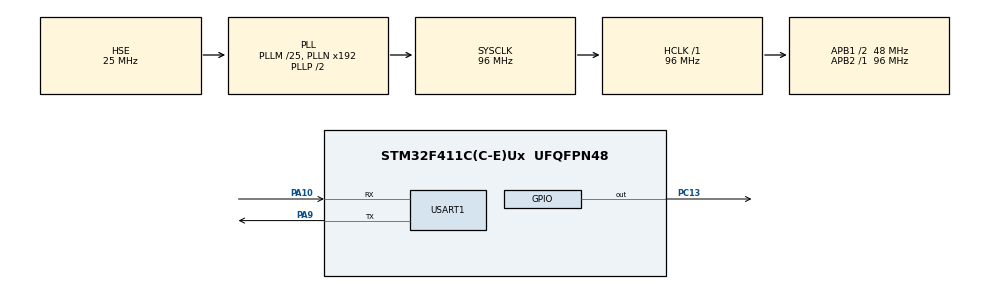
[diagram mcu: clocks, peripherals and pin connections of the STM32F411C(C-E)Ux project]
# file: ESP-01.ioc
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Mcu.Family=STM32F4
Mcu.Name=STM32F411C(C-E)Ux
Mcu.Package=UFQFPN48
NVIC.PriorityGroup=NVIC_PRIORITYGROUP_4
PA10.Mode=Asynchronous
PA10.Signal=USART1_RX
PA13.Mode=Serial_Wire
PA13.Signal=SYS_JTMS-SWDIO
PA14.Mode=Serial_Wire
PA14.Signal=SYS_JTCK-SWCLK
PA9.Mode=Asynchronous
PA9.Signal=USART1_TX
PC13-ANTI_TAMP.Signal=GPIO_Output
PH0\ -\ OSC_IN.Mode=HSE-External-Oscillator
PH0\ -\ OSC_IN.Signal=RCC_OSC_IN
PH1\ -\ OSC_OUT.Mode=HSE-External-Oscillator
PH1\ -\ OSC_OUT.Signal=RCC_OSC_OUT
ProjectManager.HeapSize=0x200
ProjectManager.StackSize=0x400
ProjectManager.TargetToolchain=STM32CubeIDE
RCC.48MHZClocksFreq_Value=48000000
RCC.AHBFreq_Value=96000000
RCC.APB1CLKDivider=RCC_HCLK_DIV2
RCC.APB1Freq_Value=48000000
RCC.APB1TimFreq_Value=96000000
RCC.APB2Freq_Value=96000000
RCC.APB2TimFreq_Value=96000000
RCC.CortexFreq_Value=96000000
RCC.HCLKFreq_Value=96000000
RCC.HSE_VALUE=25000000
RCC.HSI_VALUE=16000000
RCC.LSE_VALUE=32768
RCC.PLLM=25
RCC.PLLSourceVirtual=RCC_PLLSOURCE_HSE
RCC.SYSCLKFreq_VALUE=96000000
RCC.SYSCLKSource=RCC_SYSCLKSOURCE_PLLCLK
RCC.VCOOutputFreq_Value=192000000
USART1.VirtualMode=VM_ASYNC
board=custom

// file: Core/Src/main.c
/* USER CODE BEGIN Header */
/**
 ******************************************************************************
 * @file           : main.c
 * @brief          : Main program body
 ******************************************************************************
 * @attention
 *
 * Copyright (c) 2024 STMicroelectronics.
 * All rights reserved.
 *
 * This software is licensed under terms that can be found in the LICENSE file
 * in the root directory of this software component.
 * If no LICENSE file comes with this software, it is provided AS-IS.
 *
 ******************************************************************************
 */
/* USER CODE END Header */
#include "main.h"

/* USER CODE BEGIN Includes */
#include "stdio.h"
#include "string.h"

/* USER CODE END Includes */

/* USER CODE BEGIN PD */
#define BUFFER_LENGTH 64

/* USER CODE END PD */

UART_HandleTypeDef huart1;

void SystemClock_Config(void);
static void MX_GPIO_Init(void);
static void MX_USART1_UART_Init(void);

/* USER CODE BEGIN 0 */
int _write(int file, char *ptr, int len) {
	int DataIdx;
	for (DataIdx = 0; DataIdx < len; DataIdx++) {
		ITM_SendChar(*ptr++);
	}
	return len;
}

/* USER CODE END 0 */

int main(void) {

	/* MCU Configuration--------------------------------------------------------*/

	/* Reset of all peripherals, Initializes the Flash interface and the Systick. */
	HAL_Init();

	/* Configure the system clock */
	SystemClock_Config();

	/* Initialize all configured peripherals */
	MX_GPIO_Init();
	MX_USART1_UART_Init();
	/* USER CODE BEGIN 2 */
	char ATcommand[256];
	char message[256];

	uint8_t ATisOK = 0;
	uint8_t rxBuffer[2048] = { 0 };

	sprintf(ATcommand, "AT+RST\r\n");
	memset(rxBuffer, 0, sizeof(rxBuffer));
	HAL_UART_Transmit(&huart1, (uint8_t*) ATcommand, strlen(ATcommand), 1000);
	HAL_UART_Receive(&huart1, rxBuffer, sizeof(rxBuffer), 1000);
	printf("ESP01 reset\n\r");
	HAL_Delay(500);

	printf("Enabling STA...\r");
	ATisOK = 0;
	while (!ATisOK) {
		sprintf(ATcommand, "AT+CWMODE_CUR=1\r\n");
		memset(rxBuffer, 0, sizeof(rxBuffer));
		HAL_UART_Transmit(&huart1, (uint8_t*) ATcommand, strlen(ATcommand),
				1000);
		HAL_UART_Receive(&huart1, rxBuffer, sizeof(rxBuffer), 1000);
		if (strstr((char*) rxBuffer, "OK")) {
			ATisOK = 1;
			printf("Enabled\n\r");
		}
		HAL_Delay(500);
	}

	printf("Connecting to WiFi...\r");
	ATisOK = 0;
	while (!ATisOK) {
		sprintf(ATcommand, "AT+CWJAP_CUR=\"moto x4 6475\",\"IRONMANROX\"\r\n");
		memset(rxBuffer, 0, sizeof(rxBuffer));
		HAL_UART_Transmit(&huart1, (uint8_t*) ATcommand, strlen(ATcommand),
				1000);
		HAL_UART_Receive(&huart1, rxBuffer, sizeof(rxBuffer), 20000);
		if (strstr((char*) rxBuffer, "OK")) {
			ATisOK = 1;
			printf("Connected\n\r");
		}
		HAL_Delay(500);
	}

	printf("Enabling single connection mode...\r");
	ATisOK = 0;
	while (!ATisOK) {
		sprintf(ATcommand, "AT+CIPMUX=0\r\n");
		memset(rxBuffer, 0, sizeof(rxBuffer));
		HAL_UART_Transmit(&huart1, (uint8_t*) ATcommand, strlen(ATcommand),
				1000);
		HAL_UART_Receive(&huart1, rxBuffer, sizeof(rxBuffer), 1000);
		if (strstr((char*) rxBuffer, "OK")) {
			ATisOK = 1;
			printf("Enabled\n\r");
		}
		HAL_Delay(500);
	}

	printf("Connecting to TimeZoneDB...\r");
	sprintf(ATcommand, "AT+CIPSTART=\"TCP\",\"api.timezonedb.com\",80\r\n");
	memset(rxBuffer, 0, sizeof(rxBuffer));
	HAL_UART_Transmit(&huart1, (uint8_t*) ATcommand, strlen(ATcommand), 1000);
	HAL_UART_Receive(&huart1, rxBuffer, sizeof(rxBuffer), 1000);
	printf("Connected\n\r");
	HAL_Delay(500);

	printf("Fetching data...\r");
	sprintf(message,
	    "GET /v2.1/get-time-zone?key=6XFWMPL1F4R2&format=json&by=zone&zone=Asia/Kolkata HTTP/1.1\r\n"
	    "Host: api.timezonedb.com\r\n"
	    "Connection: close\r\n\r\n");
	sprintf(ATcommand, "AT+CIPSEND=%d\r\n", strlen(message));
	memset(rxBuffer, 0, sizeof(rxBuffer));
	HAL_UART_Transmit(&huart1, (uint8_t*) ATcommand, strlen(ATcommand), 1000);
	HAL_UART_Receive(&huart1, rxBuffer, sizeof(rxBuffer), 1000);
	if (strstr((char*) rxBuffer, ">")) {
		memset(rxBuffer, 0, sizeof(rxBuffer));
		HAL_UART_Transmit(&huart1, (uint8_t*) message, strlen(message), 1000);
		HAL_UART_Receive(&huart1, rxBuffer, sizeof(rxBuffer), 1000);
		printf("%s\n\r", rxBuffer);
	}
	HAL_Delay(500);

	printf("Connecting to Open-Meteo...\r");
	sprintf(ATcommand, "AT+CIPSTART=\"TCP\",\"api.open-meteo.com\",80\r\n");
	memset(rxBuffer, 0, sizeof(rxBuffer));
	HAL_UART_Transmit(&huart1, (uint8_t*) ATcommand, strlen(ATcommand), 1000);
	HAL_UART_Receive(&huart1, rxBuffer, sizeof(rxBuffer), 1000);
	printf("Connected\n\r");
	HAL_Delay(500);

	printf("Fetching data...\r");
	sprintf(message,
		    "GET /v1/forecast?latitude=13.35&longitude=74.7833&hourly=temperature_2m&forecast_days=2 HTTP/1.1\r\n"
		    "Host: api.open-meteo.com\r\n"
		    "Connection: close\r\n\r\n");
	sprintf(ATcommand, "AT+CIPSEND=%d\r\n", strlen(message));
	memset(rxBuffer, 0, sizeof(rxBuffer));
	HAL_UART_Transmit(&huart1, (uint8_t*) ATcommand, strlen(ATcommand), 1000);
	HAL_UART_Receive(&huart1, rxBuffer, sizeof(rxBuffer), 1000);
	if (strstr((char*) rxBuffer, ">")) {
		memset(rxBuffer, 0, sizeof(rxBuffer));
		HAL_UART_Transmit(&huart1, (uint8_t*) message, strlen(message), 1000);
		HAL_UART_Receive(&huart1, rxBuffer, sizeof(rxBuffer), 1000);
		printf("%s\n\r", rxBuffer);
	}
	HAL_Delay(500);

	printf("armdude done. Thank you.\n");

	/* USER CODE END 2 */

	/* Infinite loop */
	while (1) {

	}
}

void SystemClock_Config(void) {
	RCC_OscInitTypeDef RCC_OscInitStruct = { 0 };
	RCC_ClkInitTypeDef RCC_ClkInitStruct = { 0 };

	/** Configure the main internal regulator output voltage
	 */
	__HAL_RCC_PWR_CLK_ENABLE();
	__HAL_PWR_VOLTAGESCALING_CONFIG(PWR_REGULATOR_VOLTAGE_SCALE1);

	/** Initializes the RCC Oscillators according to the specified parameters
	 * in the RCC_OscInitTypeDef structure.
	 */
	RCC_OscInitStruct.OscillatorType = RCC_OSCILLATORTYPE_HSE;
	RCC_OscInitStruct.HSEState = RCC_HSE_ON;
	RCC_OscInitStruct.PLL.PLLState = RCC_PLL_ON;
	RCC_OscInitStruct.PLL.PLLSource = RCC_PLLSOURCE_HSE;
	RCC_OscInitStruct.PLL.PLLM = 25;
	RCC_OscInitStruct.PLL.PLLN = 192;
	RCC_OscInitStruct.PLL.PLLP = RCC_PLLP_DIV2;
	RCC_OscInitStruct.PLL.PLLQ = 4;
	if (HAL_RCC_OscConfig(&RCC_OscInitStruct) != HAL_OK) {
		Error_Handler();
	}

	/** Initializes the CPU, AHB and APB buses clocks
	 */
	RCC_ClkInitStruct.ClockType = RCC_CLOCKTYPE_HCLK | RCC_CLOCKTYPE_SYSCLK
			| RCC_CLOCKTYPE_PCLK1 | RCC_CLOCKTYPE_PCLK2;
	RCC_ClkInitStruct.SYSCLKSource = RCC_SYSCLKSOURCE_PLLCLK;
	RCC_ClkInitStruct.AHBCLKDivider = RCC_SYSCLK_DIV1;
	RCC_ClkInitStruct.APB1CLKDivider = RCC_HCLK_DIV2;
	RCC_ClkInitStruct.APB2CLKDivider = RCC_HCLK_DIV1;

	if (HAL_RCC_ClockConfig(&RCC_ClkInitStruct, FLASH_LATENCY_3) != HAL_OK) {
		Error_Handler();
	}
}

static void MX_USART1_UART_Init(void) {

	huart1.Instance = USART1;
	huart1.Init.BaudRate = 115200;
	huart1.Init.WordLength = UART_WORDLENGTH_8B;
	huart1.Init.StopBits = UART_STOPBITS_1;
	huart1.Init.Parity = UART_PARITY_NONE;
	huart1.Init.Mode = UART_MODE_TX_RX;
	huart1.Init.HwFlowCtl = UART_HWCONTROL_NONE;
	huart1.Init.OverSampling = UART_OVERSAMPLING_16;
	if (HAL_UART_Init(&huart1) != HAL_OK) {
		Error_Handler();
	}

}

static void MX_GPIO_Init(void) {
	GPIO_InitTypeDef GPIO_InitStruct = { 0 };

	/* GPIO Ports Clock Enable */
	__HAL_RCC_GPIOC_CLK_ENABLE();
	__HAL_RCC_GPIOH_CLK_ENABLE();
	__HAL_RCC_GPIOA_CLK_ENABLE();

	/*Configure GPIO pin Output Level */
	HAL_GPIO_WritePin(GPIOC, GPIO_PIN_13, GPIO_PIN_RESET);

	/*Configure GPIO pin : PC13 */
	GPIO_InitStruct.Pin = GPIO_PIN_13;
	GPIO_InitStruct.Mode = GPIO_MODE_OUTPUT_PP;
	GPIO_InitStruct.Pull = GPIO_NOPULL;
	GPIO_InitStruct.Speed = GPIO_SPEED_FREQ_LOW;
	HAL_GPIO_Init(GPIOC, &GPIO_InitStruct);

}

void Error_Handler(void) {
	__disable_irq();
	while (1) {
	}
}
